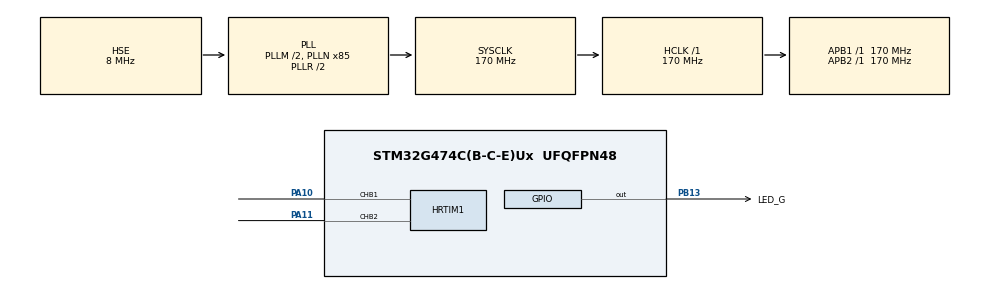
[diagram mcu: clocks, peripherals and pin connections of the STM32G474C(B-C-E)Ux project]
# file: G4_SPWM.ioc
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HRTIM1.CompareUnit1-Output_TB1TB2=HRTIM_COMPAREUNIT_1
HRTIM1.CompareValue1-Output_TB1TB2=0
HRTIM1.DeadTimeInsertion-Output_TB1TB2=HRTIM_TIMDEADTIMEINSERTION_ENABLED
HRTIM1.FallingValue-Output_TB1TB2=200
HRTIM1.NumberResetSource1-Output_TB1TB2=1
HRTIM1.NumberSetSource1-Output_TB1TB2=1
HRTIM1.Periode_TB=11333
HRTIM1.PreloadEnable-Output_TB1TB2=HRTIM_PRELOAD_ENABLED
HRTIM1.PrescalerRatio_TB=HRTIM_PRESCALERRATIO_DIV1
HRTIM1.RepetitionUpdate-Output_TB1TB2=HRTIM_UPDATEONREPETITION_ENABLED
HRTIM1.ResetOutput1_Source1-Output_TB1TB2=HRTIM_OUTPUTRESET_TIMCMP1
HRTIM1.RisingValue-Output_TB1TB2=200
HRTIM1.SetOutput1_Source1-Output_TB1TB2=HRTIM_OUTPUTSET_TIMPER
Mcu.Family=STM32G4
Mcu.Name=STM32G474C(B-C-E)Ux
Mcu.Package=UFQFPN48
NVIC.HRTIM1_TIMB_IRQn=true\:0\:0\:false\:false\:true\:true\:true\:true
NVIC.PriorityGroup=NVIC_PRIORITYGROUP_4
NVIC.TIM2_IRQn=true\:0\:0\:false\:false\:true\:true\:true\:true
PA10.Mode=Output_TB1TB2
PA10.Signal=HRTIM1_CHB1
PA11.Mode=Output_TB1TB2
PA11.Signal=HRTIM1_CHB2
PA13.Mode=Serial_Wire
PA13.Signal=SYS_JTMS-SWDIO
PA14.Mode=Serial_Wire
PA14.Signal=SYS_JTCK-SWCLK
PB13.GPIO_Label=LED_G
PB13.Signal=GPIO_Output
PF0-OSC_IN.Mode=HSE-External-Oscillator
PF0-OSC_IN.Signal=RCC_OSC_IN
PF1-OSC_OUT.Mode=HSE-External-Oscillator
PF1-OSC_OUT.Signal=RCC_OSC_OUT
ProjectManager.HeapSize=0x200
ProjectManager.StackSize=0x400
ProjectManager.TargetToolchain=STM32CubeIDE
RCC.ADC12Freq_Value=170000000
RCC.ADC345Freq_Value=170000000
RCC.AHBFreq_Value=170000000
RCC.APB1Freq_Value=170000000
RCC.APB1TimFreq_Value=170000000
RCC.APB2Freq_Value=170000000
RCC.APB2TimFreq_Value=170000000
RCC.CortexFreq_Value=170000000
RCC.EXTERNAL_CLOCK_VALUE=12288000
RCC.HCLKFreq_Value=170000000
RCC.HSE_VALUE=8000000
RCC.HSI48_VALUE=48000000
RCC.HSI_VALUE=16000000
RCC.LSE_VALUE=32768
RCC.PLLM=RCC_PLLM_DIV2
RCC.PLLN=85
RCC.PLLSourceVirtual=RCC_PLLSOURCE_HSE
RCC.SYSCLKFreq_VALUE=170000000
RCC.SYSCLKSource=RCC_SYSCLKSOURCE_PLLCLK
RCC.USBFreq_Value=170000000
RCC.VCOOutputFreq_Value=340000000
TIM2.PeriodNoDither=66
TIM2.Prescaler=169
VP_CORDIC_VS_CORDIC.Mode=CORDIC_Activate
VP_SYS_VS_DBSignals.Mode=DisableDeadBatterySignals
VP_TIM2_VS_ClockSourceINT.Mode=Internal
board=custom

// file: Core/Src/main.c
/* USER CODE BEGIN Header */
/**
  ******************************************************************************
  * @file           : main.c
  * @brief          : Main program body
  ******************************************************************************
  * @attention
  *
  * Copyright (c) 2025 STMicroelectronics.
  * All rights reserved.
  *
  * This software is licensed under terms that can be found in the LICENSE file
  * in the root directory of this software component.
  * If no LICENSE file comes with this software, it is provided AS-IS.
  *
  ******************************************************************************
  */
/* USER CODE END Header */
#include "main.h"

/* USER CODE BEGIN Includes */
#include <math.h>
#include "spwm.h"
#include "SEGGER_RTT.h"
#include <stdio.h>
#include <sys/errno.h>
/* USER CODE END Includes */

/* USER CODE BEGIN PM */
#define printf(...) SEGGER_RTT_printf(0, ##__VA_ARGS__)
/* USER CODE END PM */

CORDIC_HandleTypeDef hcordic;

HRTIM_HandleTypeDef hhrtim1;

TIM_HandleTypeDef htim2;

void SystemClock_Config(void);
static void MX_GPIO_Init(void);
static void MX_HRTIM1_Init(void);
static void MX_CORDIC_Init(void);
static void MX_TIM2_Init(void);

/* USER CODE BEGIN 0 */
int _write(int file, char* ptr, int len)
{
  if (file == 1 /* stdout */ || file == 2 /* stderr */)
  {
    return SEGGER_RTT_Write(0, ptr, len);
  }
  errno = EBADF;
  return -1;
}

void HAL_TIM_PeriodElapsedCallback(TIM_HandleTypeDef *htim)
{
  if (htim->Instance == TIM2)
  {
    spwm_update();
  }
}

/* USER CODE END 0 */

int main(void)
{

  /* MCU Configuration--------------------------------------------------------*/

  /* Reset of all peripherals, Initializes the Flash interface and the Systick. */
  HAL_Init();

  /* Configure the system clock */
  SystemClock_Config();

  /* Initialize all configured peripherals */
  MX_GPIO_Init();
  MX_HRTIM1_Init();
  MX_CORDIC_Init();
  MX_TIM2_Init();
  /* USER CODE BEGIN 2 */
  SEGGER_RTT_Init();
  printf("System Init...\r\n");

  HAL_HRTIM_WaveformCounterStart(&hhrtim1, HRTIM_TIMERID_TIMER_B);
  HAL_HRTIM_WaveformOutputStart(&hhrtim1, HRTIM_OUTPUT_TB1 | HRTIM_OUTPUT_TB2);

  spwm_init(11333);
  spwm_start();
  HAL_TIM_Base_Start_IT(&htim2);

  // __HAL_HRTIM_SETCOMPARE(&hhrtim1, HRTIM_TIMERINDEX_TIMER_B, HRTIM_COMPAREUNIT_1, 1000);
  /* USER CODE END 2 */

  /* Infinite loop */
  /* USER CODE BEGIN WHILE */
  while (1)
  {
    HAL_GPIO_TogglePin(LED_G_GPIO_Port, LED_G_Pin);
    /* USER CODE END WHILE */

  }
}

void SystemClock_Config(void)
{
  RCC_OscInitTypeDef RCC_OscInitStruct = {0};
  RCC_ClkInitTypeDef RCC_ClkInitStruct = {0};

  /** Configure the main internal regulator output voltage
  */
  HAL_PWREx_ControlVoltageScaling(PWR_REGULATOR_VOLTAGE_SCALE1_BOOST);

  /** Initializes the RCC Oscillators according to the specified parameters
  * in the RCC_OscInitTypeDef structure.
  */
  RCC_OscInitStruct.OscillatorType = RCC_OSCILLATORTYPE_HSE;
  RCC_OscInitStruct.HSEState = RCC_HSE_ON;
  RCC_OscInitStruct.PLL.PLLState = RCC_PLL_ON;
  RCC_OscInitStruct.PLL.PLLSource = RCC_PLLSOURCE_HSE;
  RCC_OscInitStruct.PLL.PLLM = RCC_PLLM_DIV2;
  RCC_OscInitStruct.PLL.PLLN = 85;
  RCC_OscInitStruct.PLL.PLLP = RCC_PLLP_DIV2;
  RCC_OscInitStruct.PLL.PLLQ = RCC_PLLQ_DIV2;
  RCC_OscInitStruct.PLL.PLLR = RCC_PLLR_DIV2;
  if (HAL_RCC_OscConfig(&RCC_OscInitStruct) != HAL_OK)
  {
    Error_Handler();
  }

  /** Initializes the CPU, AHB and APB buses clocks
  */
  RCC_ClkInitStruct.ClockType = RCC_CLOCKTYPE_HCLK|RCC_CLOCKTYPE_SYSCLK
                              |RCC_CLOCKTYPE_PCLK1|RCC_CLOCKTYPE_PCLK2;
  RCC_ClkInitStruct.SYSCLKSource = RCC_SYSCLKSOURCE_PLLCLK;
  RCC_ClkInitStruct.AHBCLKDivider = RCC_SYSCLK_DIV1;
  RCC_ClkInitStruct.APB1CLKDivider = RCC_HCLK_DIV1;
  RCC_ClkInitStruct.APB2CLKDivider = RCC_HCLK_DIV1;

  if (HAL_RCC_ClockConfig(&RCC_ClkInitStruct, FLASH_LATENCY_4) != HAL_OK)
  {
    Error_Handler();
  }
}

static void MX_CORDIC_Init(void)
{

  hcordic.Instance = CORDIC;
  if (HAL_CORDIC_Init(&hcordic) != HAL_OK)
  {
    Error_Handler();
  }

}

static void MX_HRTIM1_Init(void)
{

  HRTIM_TimeBaseCfgTypeDef pTimeBaseCfg = {0};
  HRTIM_TimerCtlTypeDef pTimerCtl = {0};
  HRTIM_TimerCfgTypeDef pTimerCfg = {0};
  HRTIM_CompareCfgTypeDef pCompareCfg = {0};
  HRTIM_DeadTimeCfgTypeDef pDeadTimeCfg = {0};
  HRTIM_OutputCfgTypeDef pOutputCfg = {0};

  hhrtim1.Instance = HRTIM1;
  hhrtim1.Init.HRTIMInterruptResquests = HRTIM_IT_NONE;
  hhrtim1.Init.SyncOptions = HRTIM_SYNCOPTION_NONE;
  if (HAL_HRTIM_Init(&hhrtim1) != HAL_OK)
  {
    Error_Handler();
  }
  if (HAL_HRTIM_DLLCalibrationStart(&hhrtim1, HRTIM_CALIBRATIONRATE_3) != HAL_OK)
  {
    Error_Handler();
  }
  if (HAL_HRTIM_PollForDLLCalibration(&hhrtim1, 10) != HAL_OK)
  {
    Error_Handler();
  }
  pTimeBaseCfg.Period = 11333;
  pTimeBaseCfg.RepetitionCounter = 0x00;
  pTimeBaseCfg.PrescalerRatio = HRTIM_PRESCALERRATIO_DIV1;
  pTimeBaseCfg.Mode = HRTIM_MODE_CONTINUOUS;
  if (HAL_HRTIM_TimeBaseConfig(&hhrtim1, HRTIM_TIMERINDEX_TIMER_B, &pTimeBaseCfg) != HAL_OK)
  {
    Error_Handler();
  }
  pTimerCtl.UpDownMode = HRTIM_TIMERUPDOWNMODE_UP;
  pTimerCtl.GreaterCMP1 = HRTIM_TIMERGTCMP1_EQUAL;
  pTimerCtl.DualChannelDacEnable = HRTIM_TIMER_DCDE_DISABLED;
  if (HAL_HRTIM_WaveformTimerControl(&hhrtim1, HRTIM_TIMERINDEX_TIMER_B, &pTimerCtl) != HAL_OK)
  {
    Error_Handler();
  }
  pTimerCfg.InterruptRequests = HRTIM_TIM_IT_NONE;
  pTimerCfg.DMARequests = HRTIM_TIM_DMA_NONE;
  pTimerCfg.DMASrcAddress = 0x0000;
  pTimerCfg.DMADstAddress = 0x0000;
  pTimerCfg.DMASize = 0x1;
  pTimerCfg.HalfModeEnable = HRTIM_HALFMODE_DISABLED;
  pTimerCfg.InterleavedMode = HRTIM_INTERLEAVED_MODE_DISABLED;
  pTimerCfg.StartOnSync = HRTIM_SYNCSTART_DISABLED;
  pTimerCfg.ResetOnSync = HRTIM_SYNCRESET_DISABLED;
  pTimerCfg.DACSynchro = HRTIM_DACSYNC_NONE;
  pTimerCfg.PreloadEnable = HRTIM_PRELOAD_ENABLED;
  pTimerCfg.UpdateGating = HRTIM_UPDATEGATING_INDEPENDENT;
  pTimerCfg.BurstMode = HRTIM_TIMERBURSTMODE_MAINTAINCLOCK;
  pTimerCfg.RepetitionUpdate = HRTIM_UPDATEONREPETITION_ENABLED;
  pTimerCfg.PushPull = HRTIM_TIMPUSHPULLMODE_DISABLED;
  pTimerCfg.FaultEnable = HRTIM_TIMFAULTENABLE_NONE;
  pTimerCfg.FaultLock = HRTIM_TIMFAULTLOCK_READWRITE;
  pTimerCfg.DeadTimeInsertion = HRTIM_TIMDEADTIMEINSERTION_ENABLED;
  pTimerCfg.DelayedProtectionMode = HRTIM_TIMER_A_B_C_DELAYEDPROTECTION_DISABLED;
  pTimerCfg.UpdateTrigger = HRTIM_TIMUPDATETRIGGER_NONE;
  pTimerCfg.ResetTrigger = HRTIM_TIMRESETTRIGGER_NONE;
  pTimerCfg.ResetUpdate = HRTIM_TIMUPDATEONRESET_DISABLED;
  pTimerCfg.ReSyncUpdate = HRTIM_TIMERESYNC_UPDATE_UNCONDITIONAL;
  if (HAL_HRTIM_WaveformTimerConfig(&hhrtim1, HRTIM_TIMERINDEX_TIMER_B, &pTimerCfg) != HAL_OK)
  {
    Error_Handler();
  }
  pCompareCfg.CompareValue = 0;
  if (HAL_HRTIM_WaveformCompareConfig(&hhrtim1, HRTIM_TIMERINDEX_TIMER_B, HRTIM_COMPAREUNIT_1, &pCompareCfg) != HAL_OK)
  {
    Error_Handler();
  }
  pDeadTimeCfg.Prescaler = HRTIM_TIMDEADTIME_PRESCALERRATIO_MUL8;
  pDeadTimeCfg.RisingValue = 200;
  pDeadTimeCfg.RisingSign = HRTIM_TIMDEADTIME_RISINGSIGN_POSITIVE;
  pDeadTimeCfg.RisingLock = HRTIM_TIMDEADTIME_RISINGLOCK_WRITE;
  pDeadTimeCfg.RisingSignLock = HRTIM_TIMDEADTIME_RISINGSIGNLOCK_WRITE;
  pDeadTimeCfg.FallingValue = 200;
  pDeadTimeCfg.FallingSign = HRTIM_TIMDEADTIME_FALLINGSIGN_POSITIVE;
  pDeadTimeCfg.FallingLock = HRTIM_TIMDEADTIME_FALLINGLOCK_WRITE;
  pDeadTimeCfg.FallingSignLock = HRTIM_TIMDEADTIME_FALLINGSIGNLOCK_WRITE;
  if (HAL_HRTIM_DeadTimeConfig(&hhrtim1, HRTIM_TIMERINDEX_TIMER_B, &pDeadTimeCfg) != HAL_OK)
  {
    Error_Handler();
  }
  pOutputCfg.Polarity = HRTIM_OUTPUTPOLARITY_HIGH;
  pOutputCfg.SetSource = HRTIM_OUTPUTSET_TIMPER;
  pOutputCfg.ResetSource = HRTIM_OUTPUTRESET_TIMCMP1;
  pOutputCfg.IdleMode = HRTIM_OUTPUTIDLEMODE_NONE;
  pOutputCfg.IdleLevel = HRTIM_OUTPUTIDLELEVEL_INACTIVE;
  pOutputCfg.FaultLevel = HRTIM_OUTPUTFAULTLEVEL_NONE;
  pOutputCfg.ChopperModeEnable = HRTIM_OUTPUTCHOPPERMODE_DISABLED;
  pOutputCfg.BurstModeEntryDelayed = HRTIM_OUTPUTBURSTMODEENTRY_REGULAR;
  if (HAL_HRTIM_WaveformOutputConfig(&hhrtim1, HRTIM_TIMERINDEX_TIMER_B, HRTIM_OUTPUT_TB1, &pOutputCfg) != HAL_OK)
  {
    Error_Handler();
  }
  pOutputCfg.SetSource = HRTIM_OUTPUTSET_NONE;
  pOutputCfg.ResetSource = HRTIM_OUTPUTRESET_NONE;
  if (HAL_HRTIM_WaveformOutputConfig(&hhrtim1, HRTIM_TIMERINDEX_TIMER_B, HRTIM_OUTPUT_TB2, &pOutputCfg) != HAL_OK)
  {
    Error_Handler();
  }
  HAL_HRTIM_MspPostInit(&hhrtim1);

}

static void MX_TIM2_Init(void)
{

  TIM_ClockConfigTypeDef sClockSourceConfig = {0};
  TIM_MasterConfigTypeDef sMasterConfig = {0};

  htim2.Instance = TIM2;
  htim2.Init.Prescaler = 169;
  htim2.Init.CounterMode = TIM_COUNTERMODE_UP;
  htim2.Init.Period = 66;
  htim2.Init.ClockDivision = TIM_CLOCKDIVISION_DIV1;
  htim2.Init.AutoReloadPreload = TIM_AUTORELOAD_PRELOAD_DISABLE;
  if (HAL_TIM_Base_Init(&htim2) != HAL_OK)
  {
    Error_Handler();
  }
  sClockSourceConfig.ClockSource = TIM_CLOCKSOURCE_INTERNAL;
  if (HAL_TIM_ConfigClockSource(&htim2, &sClockSourceConfig) != HAL_OK)
  {
    Error_Handler();
  }
  sMasterConfig.MasterOutputTrigger = TIM_TRGO_RESET;
  sMasterConfig.MasterSlaveMode = TIM_MASTERSLAVEMODE_DISABLE;
  if (HAL_TIMEx_MasterConfigSynchronization(&htim2, &sMasterConfig) != HAL_OK)
  {
    Error_Handler();
  }

}

static void MX_GPIO_Init(void)
{
  GPIO_InitTypeDef GPIO_InitStruct = {0};

  /* GPIO Ports Clock Enable */
  __HAL_RCC_GPIOF_CLK_ENABLE();
  __HAL_RCC_GPIOB_CLK_ENABLE();
  __HAL_RCC_GPIOA_CLK_ENABLE();

  /*Configure GPIO pin Output Level */
  HAL_GPIO_WritePin(LED_G_GPIO_Port, LED_G_Pin, GPIO_PIN_RESET);

  /*Configure GPIO pin : LED_G_Pin */
  GPIO_InitStruct.Pin = LED_G_Pin;
  GPIO_InitStruct.Mode = GPIO_MODE_OUTPUT_PP;
  GPIO_InitStruct.Pull = GPIO_NOPULL;
  GPIO_InitStruct.Speed = GPIO_SPEED_FREQ_LOW;
  HAL_GPIO_Init(LED_G_GPIO_Port, &GPIO_InitStruct);

}

void Error_Handler(void)
{
  __disable_irq();
  while (1)
  {
  }
}
